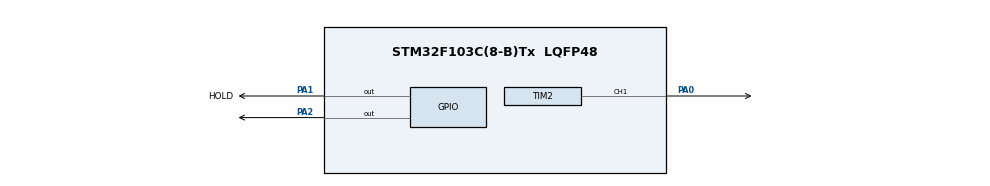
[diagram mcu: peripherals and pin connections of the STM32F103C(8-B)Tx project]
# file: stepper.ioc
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Mcu.Family=STM32F1
Mcu.Name=STM32F103C(8-B)Tx
Mcu.Package=LQFP48
NVIC.PriorityGroup=NVIC_PRIORITYGROUP_4
NVIC.TIM2_IRQn=true\:0\:0\:false\:false\:true\:true\:true\:true
PA0-WKUP.Signal=S_TIM2_CH1_ETR
PA1.GPIO_Label=HOLD
PA1.GPIO_PuPd=GPIO_PULLDOWN
PA1.GPIO_Speed=GPIO_SPEED_FREQ_HIGH
PA1.Signal=GPIO_Output
PA13.Mode=Serial_Wire
PA13.Signal=SYS_JTMS-SWDIO
PA14.Mode=Serial_Wire
PA14.Signal=SYS_JTCK-SWCLK
PA2.GPIO_PuPd=GPIO_PULLUP
PA2.GPIO_Speed=GPIO_SPEED_FREQ_HIGH
PA2.Signal=GPIO_Output
PC14-OSC32_IN.Mode=LSE-External-Oscillator
PC14-OSC32_IN.Signal=RCC_OSC32_IN
PC15-OSC32_OUT.Mode=LSE-External-Oscillator
PC15-OSC32_OUT.Signal=RCC_OSC32_OUT
PD0-OSC_IN.Mode=HSE-External-Oscillator
PD0-OSC_IN.Signal=RCC_OSC_IN
PD1-OSC_OUT.Mode=HSE-External-Oscillator
PD1-OSC_OUT.Signal=RCC_OSC_OUT
ProjectManager.HeapSize=0x200
ProjectManager.StackSize=0x400
ProjectManager.TargetToolchain=STM32CubeIDE
RCC.APB1Freq_Value=8000000
RCC.APB2Freq_Value=8000000
SH.S_TIM2_CH1_ETR.0=TIM2_CH1,PWM Generation1 CH1
TIM2.Channel-PWM\ Generation1\ CH1=TIM_CHANNEL_1
TIM2.Period=1000 - 1
TIM2.Prescaler=80 - 1
TIM2.Pulse-PWM\ Generation1\ CH1=500
VP_TIM2_VS_ClockSourceINT.Mode=Internal
board=custom

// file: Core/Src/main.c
/* USER CODE BEGIN Header */
/**
  ******************************************************************************
  * @file           : main.c
  * @brief          : Main program body
  ******************************************************************************
  * @attention
  *
  * Copyright (c) 2025 STMicroelectronics.
  * All rights reserved.
  *
  * This software is licensed under terms that can be found in the LICENSE file
  * in the root directory of this software component.
  * If no LICENSE file comes with this software, it is provided AS-IS.
  *
  ******************************************************************************
  */
/* USER CODE END Header */
#include "main.h"

TIM_HandleTypeDef htim2;

/* USER CODE BEGIN PV */
// Dùng xung PWM từ PA0 là CW: PSC = 8 - 1; ARR = 1000 - 1; CRR = 500 - 1
// Chân PA1 dùng làm chân HOLD
// Chân PA2 dùng làm chân CCW
// Điều khiển uart bằng
// mode 1: 3 + enter
// mode 2: 2 + enter
// mode 3: 3 chiều vòng + enter
/* USER CODE END PV */

void SystemClock_Config(void);
static void MX_GPIO_Init(void);
static void MX_TIM2_Init(void);
/* USER CODE BEGIN PFP */
uint8_t rx_data[10];
uint8_t rx_index = 0;
uint8_t mode;
volatile uint16_t dem = 0;
uint8_t vong = 0;
uint8_t chieu = 0;
/* USER CODE END PFP */

int main(void)
{

  /* MCU Configuration--------------------------------------------------------*/

  /* Reset of all peripherals, Initializes the Flash interface and the Systick. */
  HAL_Init();

  /* Configure the system clock */
  SystemClock_Config();

  /* Initialize all configured peripherals */
  MX_GPIO_Init();
  MX_TIM2_Init();
  /* USER CODE BEGIN 2 */
  //HAL_GPIO_WritePin(GPIOA, GPIO_PIN_2, GPIO_PIN_SET);
  //HAL_GPIO_WritePin(GPIOA, GPIO_PIN_1, GPIO_PIN_RESET);
  HAL_GPIO_WritePin(GPIOA, GPIO_PIN_2, GPIO_PIN_SET);
  //HAL_Delay(1);
  HAL_TIM_PWM_Start(&htim2, TIM_CHANNEL_1);
  //HAL_TIM_Base_Start_IT(&htim2);
  __HAL_TIM_SET_COMPARE(&htim2, TIM_CHANNEL_1,500);
  //HAL_UART_Receive_IT(&huart2, rx_data, 1);
  /* USER CODE END 2 */

  /* Infinite loop */
  while (1)
  {

  }
}

void SystemClock_Config(void)
{
  RCC_OscInitTypeDef RCC_OscInitStruct = {0};
  RCC_ClkInitTypeDef RCC_ClkInitStruct = {0};

  /** Initializes the RCC Oscillators according to the specified parameters
  * in the RCC_OscInitTypeDef structure.
  */
  RCC_OscInitStruct.OscillatorType = RCC_OSCILLATORTYPE_HSI;
  RCC_OscInitStruct.HSIState = RCC_HSI_ON;
  RCC_OscInitStruct.HSICalibrationValue = RCC_HSICALIBRATION_DEFAULT;
  RCC_OscInitStruct.PLL.PLLState = RCC_PLL_NONE;
  if (HAL_RCC_OscConfig(&RCC_OscInitStruct) != HAL_OK)
  {
    Error_Handler();
  }

  /** Initializes the CPU, AHB and APB buses clocks
  */
  RCC_ClkInitStruct.ClockType = RCC_CLOCKTYPE_HCLK|RCC_CLOCKTYPE_SYSCLK
                              |RCC_CLOCKTYPE_PCLK1|RCC_CLOCKTYPE_PCLK2;
  RCC_ClkInitStruct.SYSCLKSource = RCC_SYSCLKSOURCE_HSI;
  RCC_ClkInitStruct.AHBCLKDivider = RCC_SYSCLK_DIV1;
  RCC_ClkInitStruct.APB1CLKDivider = RCC_HCLK_DIV1;
  RCC_ClkInitStruct.APB2CLKDivider = RCC_HCLK_DIV1;

  if (HAL_RCC_ClockConfig(&RCC_ClkInitStruct, FLASH_LATENCY_0) != HAL_OK)
  {
    Error_Handler();
  }
}

static void MX_TIM2_Init(void)
{

  TIM_ClockConfigTypeDef sClockSourceConfig = {0};
  TIM_MasterConfigTypeDef sMasterConfig = {0};
  TIM_OC_InitTypeDef sConfigOC = {0};

  htim2.Instance = TIM2;
  htim2.Init.Prescaler = 8 - 1;
  htim2.Init.CounterMode = TIM_COUNTERMODE_UP;
  htim2.Init.Period = 1000 - 1;
  htim2.Init.ClockDivision = TIM_CLOCKDIVISION_DIV1;
  htim2.Init.AutoReloadPreload = TIM_AUTORELOAD_PRELOAD_DISABLE;
  if (HAL_TIM_Base_Init(&htim2) != HAL_OK)
  {
    Error_Handler();
  }
  sClockSourceConfig.ClockSource = TIM_CLOCKSOURCE_INTERNAL;
  if (HAL_TIM_ConfigClockSource(&htim2, &sClockSourceConfig) != HAL_OK)
  {
    Error_Handler();
  }
  if (HAL_TIM_PWM_Init(&htim2) != HAL_OK)
  {
    Error_Handler();
  }
  sMasterConfig.MasterOutputTrigger = TIM_TRGO_RESET;
  sMasterConfig.MasterSlaveMode = TIM_MASTERSLAVEMODE_DISABLE;
  if (HAL_TIMEx_MasterConfigSynchronization(&htim2, &sMasterConfig) != HAL_OK)
  {
    Error_Handler();
  }
  sConfigOC.OCMode = TIM_OCMODE_PWM1;
  sConfigOC.Pulse = 500 - 1;
  sConfigOC.OCPolarity = TIM_OCPOLARITY_HIGH;
  sConfigOC.OCFastMode = TIM_OCFAST_DISABLE;
  if (HAL_TIM_PWM_ConfigChannel(&htim2, &sConfigOC, TIM_CHANNEL_1) != HAL_OK)
  {
    Error_Handler();
  }
  HAL_TIM_MspPostInit(&htim2);

}

static void MX_GPIO_Init(void)
{
  GPIO_InitTypeDef GPIO_InitStruct = {0};

  /* GPIO Ports Clock Enable */
  __HAL_RCC_GPIOC_CLK_ENABLE();
  __HAL_RCC_GPIOD_CLK_ENABLE();
  __HAL_RCC_GPIOA_CLK_ENABLE();

  /*Configure GPIO pin Output Level */
  HAL_GPIO_WritePin(GPIOA, HOLD_Pin|GPIO_PIN_2, GPIO_PIN_RESET);

  /*Configure GPIO pin : HOLD_Pin */
  GPIO_InitStruct.Pin = HOLD_Pin;
  GPIO_InitStruct.Mode = GPIO_MODE_OUTPUT_PP;
  GPIO_InitStruct.Pull = GPIO_PULLDOWN;
  GPIO_InitStruct.Speed = GPIO_SPEED_FREQ_HIGH;
  HAL_GPIO_Init(HOLD_GPIO_Port, &GPIO_InitStruct);

  /*Configure GPIO pin : PA2 */
  GPIO_InitStruct.Pin = GPIO_PIN_2;
  GPIO_InitStruct.Mode = GPIO_MODE_OUTPUT_PP;
  GPIO_InitStruct.Pull = GPIO_PULLUP;
  GPIO_InitStruct.Speed = GPIO_SPEED_FREQ_HIGH;
  HAL_GPIO_Init(GPIOA, &GPIO_InitStruct);

}

/* USER CODE BEGIN 4 */
/*
void HAL_UART_RxCpltCallback(UART_HandleTypeDef *huart)
{
    if(huart->Instance == USART2)
    {
        uint8_t c = rx_data[0];

        if(c == '\n')
        {
            rx_data[rx_index] = '\0';

            // tách giá trị nhận được
            if(rx_data[0] == '1')
            {
                mode = 1;
            }
            else if(rx_data[0] == '2')
            {
                mode = 2;
            }
            else if(rx_data[0] == '3')
            {
                int v, d;
                sscanf((char*)rx_data, "3 %d %d", &v, &d); // ép kiểu thành dạng char
                mode  = 3;
                vong  = v;
                chieu = d;
            }

            rx_index = 0; //
        }
        else
        {
            rx_data[rx_index++] = c;
        }

        HAL_UART_Receive_IT(&huart2, rx_data, 1);
    }
}
*/

void HAL_TIM_PeriodElapsedCallback(TIM_HandleTypeDef *htim)
{
	dem++;
	if(mode == 1 && dem >= 500){
		dem = 0;
		HAL_GPIO_TogglePin(GPIOA, GPIO_PIN_2); // đổi chiều động cơ thay đổi ccw
	}

	if(mode == 2 && dem >= 500){
		dem = 0;
		HAL_GPIO_WritePin(GPIOA, GPIO_PIN_1, GPIO_PIN_SET); // quay 1 chiều rồi dừng động cơ
	}

	if(mode == 3){
		uint8_t dir_state = chieu;
		HAL_GPIO_WritePin(GPIOA, GPIO_PIN_2, dir_state); // đổi chiều ccw
		if(dem >= vong*500){
		HAL_GPIO_WritePin(GPIOA, GPIO_PIN_1, GPIO_PIN_SET); // dừng động cơ
		}

	}
}

void HAL_TIM_PWM_PulseFinishedCallback(TIM_HandleTypeDef *htim){
	dem++;
	if(dem >= 200){
		dem = 0;
		HAL_GPIO_WritePin(GPIOA, GPIO_PIN_1, GPIO_PIN_SET);
		//HAL_GPIO_TogglePin(GPIOA, GPIO_PIN_2);
	}
}
/* USER CODE END 4 */

void Error_Handler(void)
{
  __disable_irq();
  while (1)
  {
  }
}
